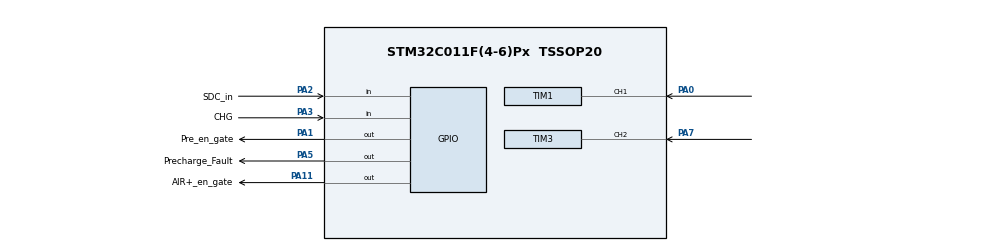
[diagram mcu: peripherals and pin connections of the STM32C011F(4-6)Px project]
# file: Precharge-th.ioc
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Mcu.Family=STM32C0
Mcu.Name=STM32C011F(4-6)Px
Mcu.Package=TSSOP20
NVIC.TIM1_BRK_UP_TRG_COM_IRQn=true\:0\:0\:false\:false\:true\:true\:true\:true
NVIC.TIM1_CC_IRQn=true\:0\:0\:false\:false\:true\:true\:true\:true
NVIC.TIM3_IRQn=true\:0\:0\:false\:false\:true\:true\:true\:true
PA0.Signal=S_TIM1_CH1
PA1.GPIO_Label=Pre_en_gate
PA1.Signal=GPIO_Output
PA11\ [PA9].GPIO_Label=AIR+_en_gate
PA11\ [PA9].Signal=GPIO_Output
PA13.Mode=Serial_Wire
PA13.Signal=DEBUG_SWDIO
PA14-BOOT0.Mode=Serial_Wire
PA14-BOOT0.Signal=DEBUG_SWCLK
PA2.GPIO_Label=SDC_in
PA2.Signal=GPIO_Input
PA3.GPIO_Label=CHG
PA3.Signal=GPIO_Input
PA5.GPIO_Label=Precharge_Fault
PA5.Signal=GPIO_Output
PA7.Signal=S_TIM3_CH2
ProjectManager.HeapSize=0x200
ProjectManager.StackSize=0x400
ProjectManager.TargetToolchain=STM32CubeIDE
RCC.ADCFreq_Value=12000000
RCC.AHBFreq_Value=12000000
RCC.CortexFreq_Value=12000000
RCC.EXTERNAL_CLOCK_VALUE=12288000
RCC.HCLKFreq_Value=12000000
RCC.HSE_VALUE=8000000
RCC.HSI_VALUE=48000000
RCC.LSE_VALUE=32768
RCC.SYSCLKFreq_VALUE=12000000
SH.S_TIM1_CH1.0=TIM1_CH1,TriggerSource_TI1FP1
SH.S_TIM1_CH1.1=TIM1_CH1,Input_Capture1_from_TI1
SH.S_TIM3_CH2.0=TIM3_CH2,Input_Capture2_from_TI2
TIM1.Channel-Input_Capture1_from_TI1=TIM_CHANNEL_1
TIM3.Channel-Input_Capture2_from_TI2=TIM_CHANNEL_2
VP_TIM1_VS_ClockSourceINT.Mode=Internal
VP_TIM1_VS_ControllerModeReset.Mode=Reset Mode
VP_TIM3_VS_ClockSourceINT.Mode=Internal
board=custom

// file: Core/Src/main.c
/* USER CODE BEGIN Header */
/**
  ******************************************************************************
  * @file           : main.c
  * @brief          : Main program body
  ******************************************************************************
  * @attention
  *
  * Copyright (c) 2026 STMicroelectronics.
  * All rights reserved.
  *
  * This software is licensed under terms that can be found in the LICENSE file
  * in the root directory of this software component.
  * If no LICENSE file comes with this software, it is provided AS-IS.
  *
  ******************************************************************************
  */
/* USER CODE END Header */
#include "main.h"

TIM_HandleTypeDef htim1;
TIM_HandleTypeDef htim3;

void SystemClock_Config(void);
static void MX_GPIO_Init(void);
static void MX_TIM1_Init(void);
static void MX_TIM3_Init(void);

int main(void)
{

  /* MCU Configuration--------------------------------------------------------*/

  /* Reset of all peripherals, Initializes the Flash interface and the Systick. */
  HAL_Init();

  /* Configure the system clock */
  SystemClock_Config();

  /* Initialize all configured peripherals */
  MX_GPIO_Init();
  MX_TIM1_Init();
  MX_TIM3_Init();

  /* Infinite loop */
  /* USER CODE BEGIN WHILE */
  while (1)
  {
	HAL_GPIO_WritePin(GPIOA, GPIO_PIN_11, GPIO_PIN_RESET);
	HAL_Delay(500);
	//HAL_GPIO_WritePin(GPIOA, GPIO_PIN_11, GPIO_PIN_SET);
    /* USER CODE END WHILE */

  }
}

void SystemClock_Config(void)
{
  RCC_OscInitTypeDef RCC_OscInitStruct = {0};
  RCC_ClkInitTypeDef RCC_ClkInitStruct = {0};

  __HAL_FLASH_SET_LATENCY(FLASH_LATENCY_0);

  /** Initializes the RCC Oscillators according to the specified parameters
  * in the RCC_OscInitTypeDef structure.
  */
  RCC_OscInitStruct.OscillatorType = RCC_OSCILLATORTYPE_HSI;
  RCC_OscInitStruct.HSIState = RCC_HSI_ON;
  RCC_OscInitStruct.HSIDiv = RCC_HSI_DIV4;
  RCC_OscInitStruct.HSICalibrationValue = RCC_HSICALIBRATION_DEFAULT;
  if (HAL_RCC_OscConfig(&RCC_OscInitStruct) != HAL_OK)
  {
    Error_Handler();
  }

  /** Initializes the CPU, AHB and APB buses clocks
  */
  RCC_ClkInitStruct.ClockType = RCC_CLOCKTYPE_HCLK|RCC_CLOCKTYPE_SYSCLK
                              |RCC_CLOCKTYPE_PCLK1;
  RCC_ClkInitStruct.SYSCLKSource = RCC_SYSCLKSOURCE_HSI;
  RCC_ClkInitStruct.SYSCLKDivider = RCC_SYSCLK_DIV1;
  RCC_ClkInitStruct.AHBCLKDivider = RCC_HCLK_DIV1;
  RCC_ClkInitStruct.APB1CLKDivider = RCC_APB1_DIV1;

  if (HAL_RCC_ClockConfig(&RCC_ClkInitStruct, FLASH_LATENCY_0) != HAL_OK)
  {
    Error_Handler();
  }
}

static void MX_TIM1_Init(void)
{

  TIM_ClockConfigTypeDef sClockSourceConfig = {0};
  TIM_SlaveConfigTypeDef sSlaveConfig = {0};
  TIM_MasterConfigTypeDef sMasterConfig = {0};
  TIM_IC_InitTypeDef sConfigIC = {0};

  htim1.Instance = TIM1;
  htim1.Init.Prescaler = 0;
  htim1.Init.CounterMode = TIM_COUNTERMODE_UP;
  htim1.Init.Period = 65535;
  htim1.Init.ClockDivision = TIM_CLOCKDIVISION_DIV1;
  htim1.Init.RepetitionCounter = 0;
  htim1.Init.AutoReloadPreload = TIM_AUTORELOAD_PRELOAD_DISABLE;
  if (HAL_TIM_Base_Init(&htim1) != HAL_OK)
  {
    Error_Handler();
  }
  sClockSourceConfig.ClockSource = TIM_CLOCKSOURCE_INTERNAL;
  if (HAL_TIM_ConfigClockSource(&htim1, &sClockSourceConfig) != HAL_OK)
  {
    Error_Handler();
  }
  if (HAL_TIM_IC_Init(&htim1) != HAL_OK)
  {
    Error_Handler();
  }
  sSlaveConfig.SlaveMode = TIM_SLAVEMODE_RESET;
  sSlaveConfig.InputTrigger = TIM_TS_TI1FP1;
  sSlaveConfig.TriggerPolarity = TIM_INPUTCHANNELPOLARITY_RISING;
  sSlaveConfig.TriggerFilter = 0;
  if (HAL_TIM_SlaveConfigSynchro(&htim1, &sSlaveConfig) != HAL_OK)
  {
    Error_Handler();
  }
  sMasterConfig.MasterOutputTrigger = TIM_TRGO_RESET;
  sMasterConfig.MasterOutputTrigger2 = TIM_TRGO2_RESET;
  sMasterConfig.MasterSlaveMode = TIM_MASTERSLAVEMODE_DISABLE;
  if (HAL_TIMEx_MasterConfigSynchronization(&htim1, &sMasterConfig) != HAL_OK)
  {
    Error_Handler();
  }
  sConfigIC.ICPolarity = TIM_INPUTCHANNELPOLARITY_RISING;
  sConfigIC.ICSelection = TIM_ICSELECTION_DIRECTTI;
  sConfigIC.ICPrescaler = TIM_ICPSC_DIV1;
  sConfigIC.ICFilter = 0;
  if (HAL_TIM_IC_ConfigChannel(&htim1, &sConfigIC, TIM_CHANNEL_1) != HAL_OK)
  {
    Error_Handler();
  }

}

static void MX_TIM3_Init(void)
{

  TIM_ClockConfigTypeDef sClockSourceConfig = {0};
  TIM_MasterConfigTypeDef sMasterConfig = {0};
  TIM_IC_InitTypeDef sConfigIC = {0};

  htim3.Instance = TIM3;
  htim3.Init.Prescaler = 0;
  htim3.Init.CounterMode = TIM_COUNTERMODE_UP;
  htim3.Init.Period = 65535;
  htim3.Init.ClockDivision = TIM_CLOCKDIVISION_DIV1;
  htim3.Init.AutoReloadPreload = TIM_AUTORELOAD_PRELOAD_DISABLE;
  if (HAL_TIM_Base_Init(&htim3) != HAL_OK)
  {
    Error_Handler();
  }
  sClockSourceConfig.ClockSource = TIM_CLOCKSOURCE_INTERNAL;
  if (HAL_TIM_ConfigClockSource(&htim3, &sClockSourceConfig) != HAL_OK)
  {
    Error_Handler();
  }
  if (HAL_TIM_IC_Init(&htim3) != HAL_OK)
  {
    Error_Handler();
  }
  sMasterConfig.MasterOutputTrigger = TIM_TRGO_RESET;
  sMasterConfig.MasterSlaveMode = TIM_MASTERSLAVEMODE_DISABLE;
  if (HAL_TIMEx_MasterConfigSynchronization(&htim3, &sMasterConfig) != HAL_OK)
  {
    Error_Handler();
  }
  sConfigIC.ICPolarity = TIM_INPUTCHANNELPOLARITY_RISING;
  sConfigIC.ICSelection = TIM_ICSELECTION_DIRECTTI;
  sConfigIC.ICPrescaler = TIM_ICPSC_DIV1;
  sConfigIC.ICFilter = 0;
  if (HAL_TIM_IC_ConfigChannel(&htim3, &sConfigIC, TIM_CHANNEL_2) != HAL_OK)
  {
    Error_Handler();
  }

}

static void MX_GPIO_Init(void)
{
  GPIO_InitTypeDef GPIO_InitStruct = {0};

  /* GPIO Ports Clock Enable */
  __HAL_RCC_GPIOA_CLK_ENABLE();

  /*Configure GPIO pin Output Level */
  HAL_GPIO_WritePin(GPIOA, Pre_en_gate_Pin|Precharge_Fault_Pin|AIR__en_gate_Pin, GPIO_PIN_RESET);

  /*Configure GPIO pins : Pre_en_gate_Pin Precharge_Fault_Pin AIR__en_gate_Pin */
  GPIO_InitStruct.Pin = Pre_en_gate_Pin|Precharge_Fault_Pin|AIR__en_gate_Pin;
  GPIO_InitStruct.Mode = GPIO_MODE_OUTPUT_PP;
  GPIO_InitStruct.Pull = GPIO_NOPULL;
  GPIO_InitStruct.Speed = GPIO_SPEED_FREQ_LOW;
  HAL_GPIO_Init(GPIOA, &GPIO_InitStruct);

  /*Configure GPIO pins : SDC_in_Pin CHG_Pin */
  GPIO_InitStruct.Pin = SDC_in_Pin|CHG_Pin;
  GPIO_InitStruct.Mode = GPIO_MODE_INPUT;
  GPIO_InitStruct.Pull = GPIO_NOPULL;
  HAL_GPIO_Init(GPIOA, &GPIO_InitStruct);

}

void Error_Handler(void)
{
  __disable_irq();
  while (1)
  {
  }
}
